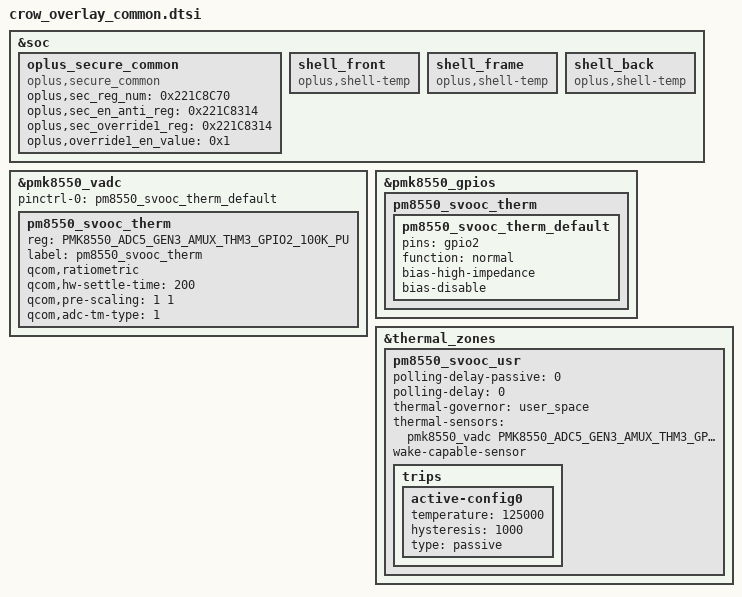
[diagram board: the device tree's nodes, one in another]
&soc {
    //#ifdef OPLUS_FEATURE_SECURITY_COMMON
    oplus_secure_common {
        compatible = "oplus,secure_common";
        oplus,sec_reg_num = <0x221C8C70>;
        oplus,sec_en_anti_reg = <0x221C8314>;
        oplus,sec_override1_reg = <0x221C8314>;
        oplus,override1_en_value = <0x1>;
    };
    //#endif /*OPLUS_FEATURE_SECURITY_COMMON*/

    //#ifdef OPLUS_FEATURE_THERMAL_HORAE
	shell_front {
        compatible = "oplus,shell-temp";
	};

	shell_frame {
        compatible = "oplus,shell-temp";
	};

	shell_back {
        compatible = "oplus,shell-temp";
	};
	//#endif /* OPLUS_FEATURE_THERMAL_HORAE */
};
// Add the thermistors of svooc
&pmk8550_vadc {
	pinctrl-0 = <&pm8550_svooc_therm_default>;
	pinctrl-names = "default";

	pm8550_svooc_therm {
        reg = <PMK8550_ADC5_GEN3_AMUX_THM3_GPIO2_100K_PU>;
        label = "pm8550_svooc_therm";
        qcom,ratiometric;
        qcom,hw-settle-time = <200>;
        qcom,pre-scaling = <1 1>;
        qcom,adc-tm-type = <1>;
	};
};

&pmk8550_gpios {
	pm8550_svooc_therm {
		pm8550_svooc_therm_default: pm8550_svooc_therm_default {
			pins = "gpio2";
			function = "normal"; //normal
			bias-high-impedance;
			bias-disable;
		};
	};
};

&thermal_zones {

	pm8550_svooc_usr {
		polling-delay-passive = <0>;
		polling-delay = <0>;
		thermal-governor = "user_space";
		thermal-sensors = <&pmk8550_vadc PMK8550_ADC5_GEN3_AMUX_THM3_GPIO2_100K_PU>;
		wake-capable-sensor;
		trips {
			active-config0 {
				temperature = <125000>;
				hysteresis = <1000>;
				type = "passive";
			};
		};
	};

};
